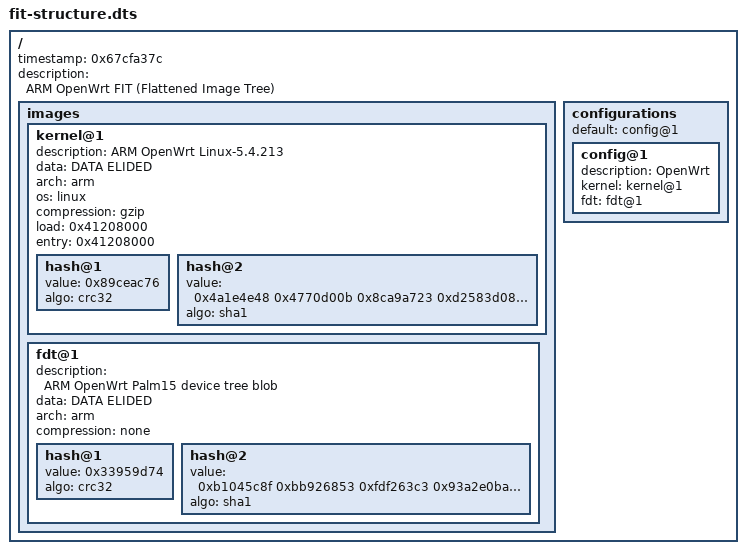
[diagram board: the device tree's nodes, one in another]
/dts-v1/;

/ {
	timestamp = <0x67cfa37c>;
	description = "ARM OpenWrt FIT (Flattened Image Tree)";
	#address-cells = <0x01>;

	images {

		kernel@1 {
			description = "ARM OpenWrt Linux-5.4.213";
			data = <DATA ELIDED>
			type = "kernel";
			arch = "arm";
			os = "linux";
			compression = "gzip";
			load = <0x41208000>;
			entry = <0x41208000>;

			hash@1 {
				value = <0x89ceac76>;
				algo = "crc32";
			};

			hash@2 {
				value = <0x4a1e4e48 0x4770d00b 0x8ca9a723 0xd2583d08 0x594d61eb>;
				algo = "sha1";
			};
		};

		fdt@1 {
			description = "ARM OpenWrt Palm15 device tree blob";
			data = <DATA ELIDED>
			type = "flat_dt";
			arch = "arm";
			compression = "none";

			hash@1 {
				value = <0x33959d74>;
				algo = "crc32";
			};

			hash@2 {
				value = <0xb1045c8f 0xbb926853 0xfdf263c3 0x93a2e0ba 0xbe3ebcf4>;
				algo = "sha1";
			};
		};
	};

	configurations {
		default = "config@1";

		config@1 {
			description = "OpenWrt";
			kernel = "kernel@1";
			fdt = "fdt@1";
		};
	};
};
